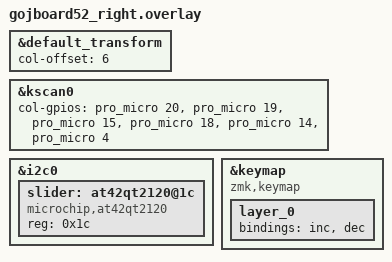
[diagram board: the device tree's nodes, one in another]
/*
 * Copyright (c) 2020 Pete Johanson
 *
 * SPDX-License-Identifier: MIT
 */

#include "gojboard52.dtsi"

&default_transform {
    col-offset = <6>;
};

&kscan0 {
    col-gpios
        = <&pro_micro 20 GPIO_ACTIVE_HIGH>
        , <&pro_micro 19 GPIO_ACTIVE_HIGH>
        , <&pro_micro 15 GPIO_ACTIVE_HIGH>
        , <&pro_micro 18 GPIO_ACTIVE_HIGH>
        , <&pro_micro 14 GPIO_ACTIVE_HIGH>
        , <&pro_micro  4 GPIO_ACTIVE_HIGH>
        ;
};

&i2c0 {
    status = "okay";
    slider: at42qt2120@1c {
        compatible = "microchip,at42qt2120";
        reg = <0x1c>;
        // change-gpios = <&gpio1 14 GPIO_ACTIVE_LOW>;
    };
};

&keymap {
    compatible = "zmk,keymap";
    layer_0 {
        bindings = <
            &inc &dec
        >;
    };
};
